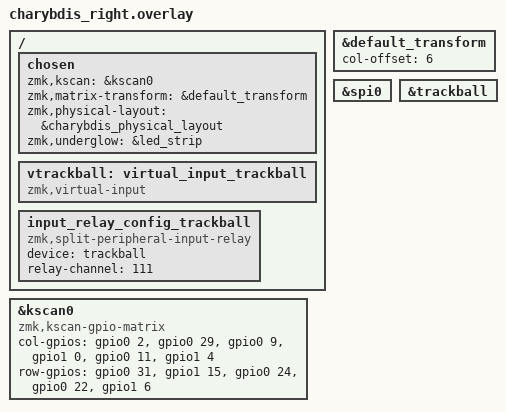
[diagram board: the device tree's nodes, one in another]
#include "charybdis.dtsi"
#include "charybdis_pmw3610.dtsi"
#include "charybdis-layouts.dtsi"

// The matrix transform is 6 columns over because the left half is 6 columns wide.
&default_transform {
	col-offset = <6>;
};

/ {
    chosen {
        zmk,kscan = &kscan0;
		zmk,matrix-transform = &default_transform;
        zmk,physical-layout = &charybdis_physical_layout;
        zmk,underglow = &led_strip;
    };
};

&kscan0 {
	compatible = "zmk,kscan-gpio-matrix";
	
	col-gpios
		= <&gpio0 2 (GPIO_ACTIVE_HIGH | GPIO_PULL_DOWN)>
		, <&gpio0 29 (GPIO_ACTIVE_HIGH | GPIO_PULL_DOWN)>
		, <&gpio0 9 (GPIO_ACTIVE_HIGH | GPIO_PULL_DOWN)>
		, <&gpio1 0  (GPIO_ACTIVE_HIGH | GPIO_PULL_DOWN)>
		, <&gpio0 11 (GPIO_ACTIVE_HIGH | GPIO_PULL_DOWN)>
		, <&gpio1 4  (GPIO_ACTIVE_HIGH | GPIO_PULL_DOWN)>
		;

	row-gpios
    = <&gpio0 31 GPIO_ACTIVE_HIGH>
    , <&gpio1 15 GPIO_ACTIVE_HIGH>
    , <&gpio0 24 GPIO_ACTIVE_HIGH>
	  , <&gpio0 22 GPIO_ACTIVE_HIGH>
    , <&gpio1 6  GPIO_ACTIVE_HIGH>
    ;
};

&spi0 {
    status = "okay";
};

&trackball {
    status = "okay";
};

/ {
	vtrackball: virtual_input_trackball {
		compatible = "zmk,virtual-input";
	};

	input_relay_config_trackball {
		compatible = "zmk,split-peripheral-input-relay";
		device = <&trackball>;
		relay-channel = <111>;
	};
};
